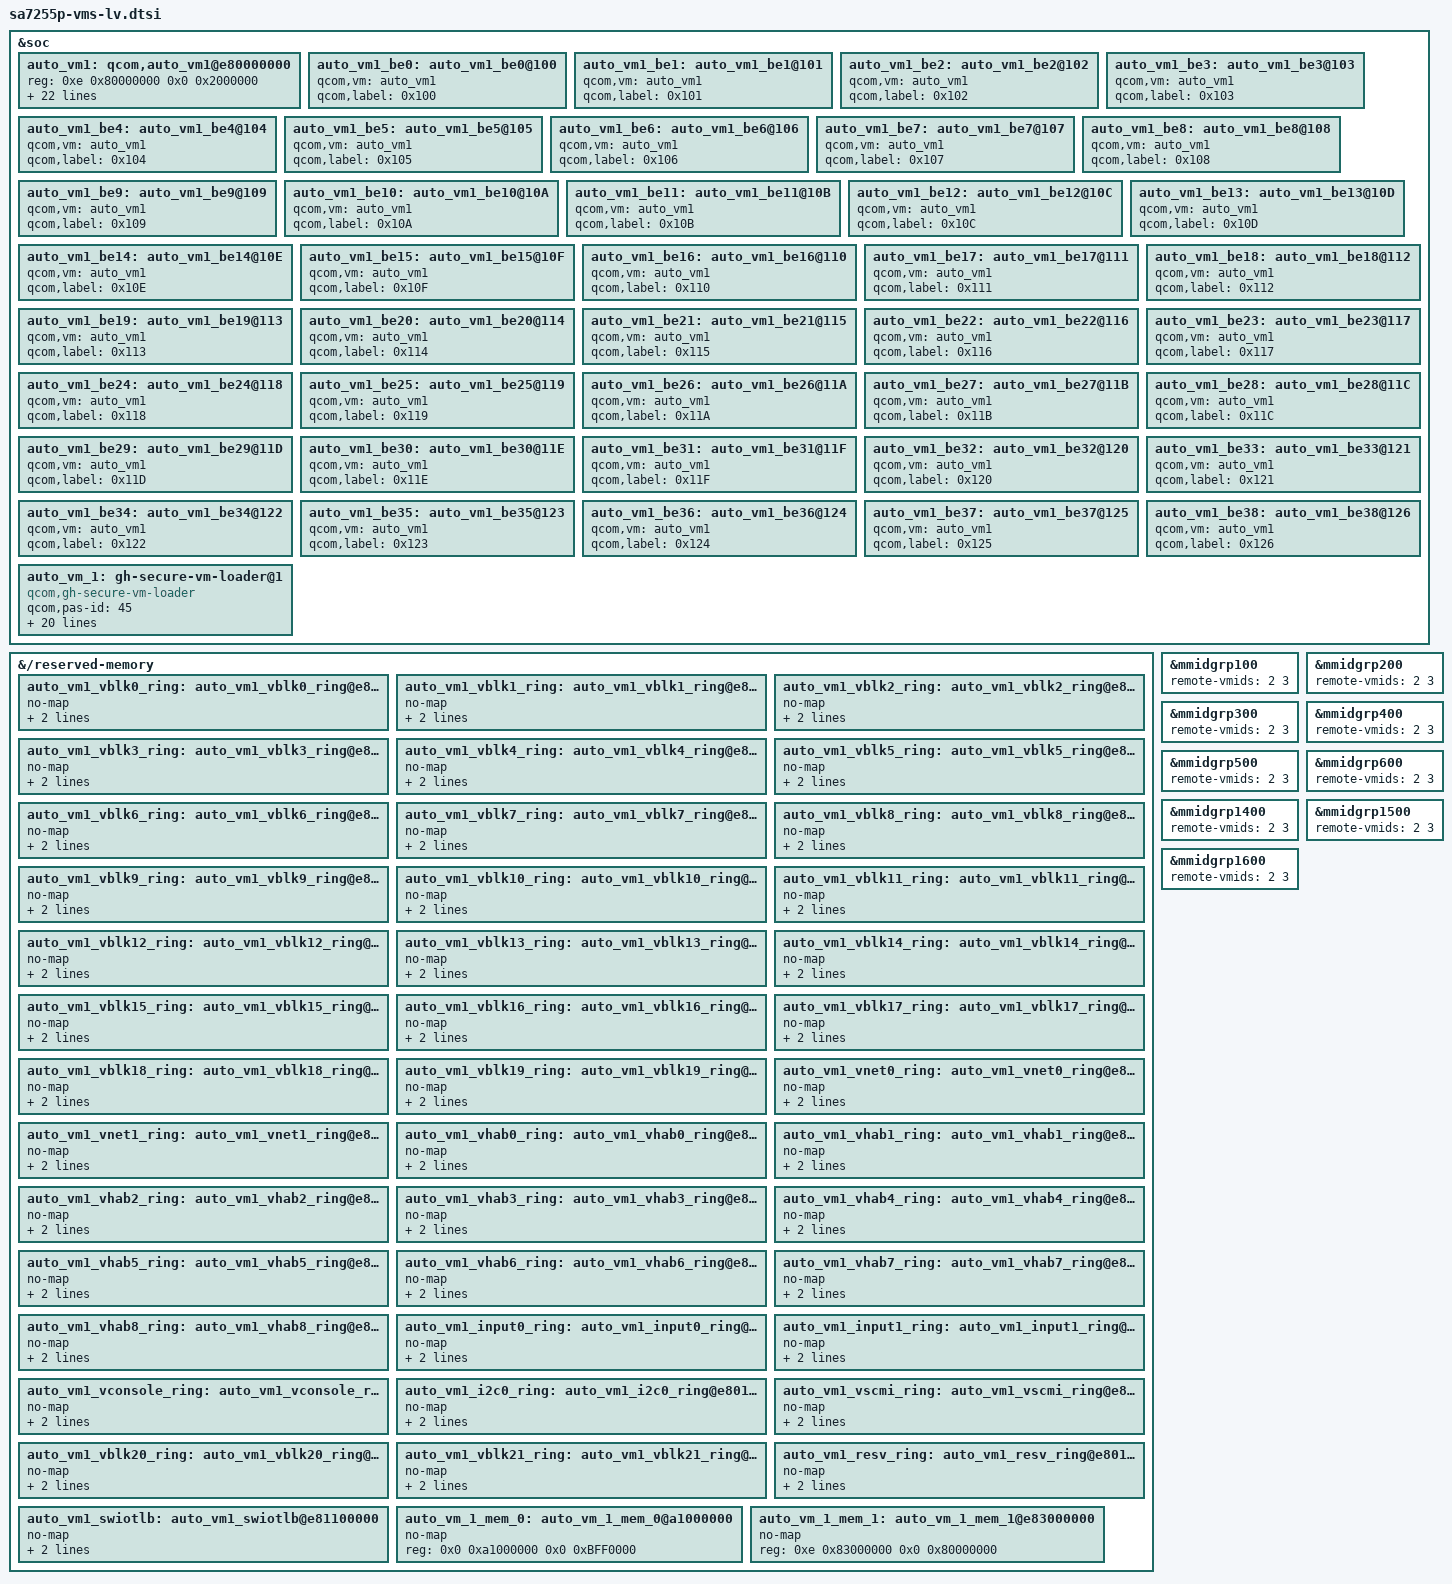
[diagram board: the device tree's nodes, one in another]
// SPDX-License-Identifier: BSD-3-Clause
/*
 * Copyright (c) Qualcomm Technologies, Inc. and/or its subsidiaries.
 */

&soc {
	auto_vm1: qcom,auto_vm1@e80000000 {
		reg = <0xe 0x80000000 0x0 0x2000000>; /*32MB*/
		vm_name = "autoghgvmlv";
		shared-buffers = <&auto_vm1_vblk0_ring
				&auto_vm1_vblk1_ring
				&auto_vm1_vblk2_ring
				&auto_vm1_vblk3_ring
				&auto_vm1_vblk4_ring
				&auto_vm1_vblk5_ring
				&auto_vm1_vblk6_ring
				&auto_vm1_vblk7_ring
				&auto_vm1_vblk8_ring
				&auto_vm1_vblk9_ring
				&auto_vm1_vblk10_ring
				&auto_vm1_vblk11_ring
				&auto_vm1_vblk12_ring
				&auto_vm1_vblk13_ring
				&auto_vm1_vblk14_ring
				&auto_vm1_vblk15_ring
				&auto_vm1_vblk16_ring
				&auto_vm1_vblk17_ring
				&auto_vm1_vblk18_ring
				&auto_vm1_vblk19_ring
				&auto_vm1_vblk20_ring
				&auto_vm1_vblk21_ring
				&auto_vm1_vnet0_ring
				&auto_vm1_vnet1_ring
				&auto_vm1_vhab0_ring
				&auto_vm1_vhab1_ring
				&auto_vm1_vhab2_ring
				&auto_vm1_vhab3_ring
				&auto_vm1_vhab4_ring
				&auto_vm1_vhab5_ring
				&auto_vm1_vhab6_ring
				&auto_vm1_vhab7_ring
				&auto_vm1_vhab8_ring
				&auto_vm1_input0_ring
				&auto_vm1_input1_ring
				&auto_vm1_vconsole_ring
				&auto_vm1_i2c0_ring
				&auto_vm1_vscmi_ring
				&auto_vm1_resv_ring
				&auto_vm1_swiotlb>;
	};

	auto_vm1_be0: auto_vm1_be0@100 {
		qcom,vm = <&auto_vm1>;
		qcom,label = <0x100>;
	};

	auto_vm1_be1: auto_vm1_be1@101 {
		qcom,vm = <&auto_vm1>;
		qcom,label = <0x101>;
	};

	auto_vm1_be2: auto_vm1_be2@102 {
		qcom,vm = <&auto_vm1>;
		qcom,label = <0x102>;
	};

	auto_vm1_be3: auto_vm1_be3@103 {
		qcom,vm = <&auto_vm1>;
		qcom,label = <0x103>;
	};

	auto_vm1_be4: auto_vm1_be4@104 {
		qcom,vm = <&auto_vm1>;
		qcom,label = <0x104>;
	};

	auto_vm1_be5: auto_vm1_be5@105 {
		qcom,vm = <&auto_vm1>;
		qcom,label = <0x105>;
	};

	auto_vm1_be6: auto_vm1_be6@106 {
		qcom,vm = <&auto_vm1>;
		qcom,label = <0x106>;
	};

	auto_vm1_be7: auto_vm1_be7@107 {
		qcom,vm = <&auto_vm1>;
		qcom,label = <0x107>;
	};

	auto_vm1_be8: auto_vm1_be8@108 {
		qcom,vm = <&auto_vm1>;
		qcom,label = <0x108>;
	};

	auto_vm1_be9: auto_vm1_be9@109 {
		qcom,vm = <&auto_vm1>;
		qcom,label = <0x109>;
	};

	auto_vm1_be10: auto_vm1_be10@10A {
		qcom,vm = <&auto_vm1>;
		qcom,label = <0x10A>;
	};

	auto_vm1_be11: auto_vm1_be11@10B {
		qcom,vm = <&auto_vm1>;
		qcom,label = <0x10B>;
	};

	auto_vm1_be12: auto_vm1_be12@10C {
		qcom,vm = <&auto_vm1>;
		qcom,label = <0x10C>;
	};

	auto_vm1_be13: auto_vm1_be13@10D {
		qcom,vm = <&auto_vm1>;
		qcom,label = <0x10D>;
	};

	auto_vm1_be14: auto_vm1_be14@10E {
		qcom,vm = <&auto_vm1>;
		qcom,label = <0x10E>;
	};

	auto_vm1_be15: auto_vm1_be15@10F {
		qcom,vm = <&auto_vm1>;
		qcom,label = <0x10F>;
	};

	auto_vm1_be16: auto_vm1_be16@110 {
		qcom,vm = <&auto_vm1>;
		qcom,label = <0x110>;
	};

	auto_vm1_be17: auto_vm1_be17@111 {
		qcom,vm = <&auto_vm1>;
		qcom,label = <0x111>;
	};

	auto_vm1_be18: auto_vm1_be18@112 {
		qcom,vm = <&auto_vm1>;
		qcom,label = <0x112>;
	};

	auto_vm1_be19: auto_vm1_be19@113 {
		qcom,vm = <&auto_vm1>;
		qcom,label = <0x113>;
	};

	auto_vm1_be20: auto_vm1_be20@114 {
		qcom,vm = <&auto_vm1>;
		qcom,label = <0x114>;
	};

	auto_vm1_be21: auto_vm1_be21@115 {
		qcom,vm = <&auto_vm1>;
		qcom,label = <0x115>;
	};

	auto_vm1_be22: auto_vm1_be22@116 {
		qcom,vm = <&auto_vm1>;
		qcom,label = <0x116>;
	};

	auto_vm1_be23: auto_vm1_be23@117 {
		qcom,vm = <&auto_vm1>;
		qcom,label = <0x117>;
	};

	auto_vm1_be24: auto_vm1_be24@118 {
		qcom,vm = <&auto_vm1>;
		qcom,label = <0x118>;
	};

	auto_vm1_be25: auto_vm1_be25@119 {
		qcom,vm = <&auto_vm1>;
		qcom,label = <0x119>;
	};

	auto_vm1_be26: auto_vm1_be26@11A {
		qcom,vm = <&auto_vm1>;
		qcom,label = <0x11A>;
	};

	auto_vm1_be27: auto_vm1_be27@11B {
		qcom,vm = <&auto_vm1>;
		qcom,label = <0x11B>;
	};

	auto_vm1_be28: auto_vm1_be28@11C {
		qcom,vm = <&auto_vm1>;
		qcom,label = <0x11C>;
	};

	auto_vm1_be29: auto_vm1_be29@11D {
		qcom,vm = <&auto_vm1>;
		qcom,label = <0x11D>;
	};

	auto_vm1_be30: auto_vm1_be30@11E {
		qcom,vm = <&auto_vm1>;
		qcom,label = <0x11E>;
	};

	auto_vm1_be31: auto_vm1_be31@11F {
		qcom,vm = <&auto_vm1>;
		qcom,label = <0x11F>;
	};

	auto_vm1_be32: auto_vm1_be32@120 {
		qcom,vm = <&auto_vm1>;
		qcom,label = <0x120>;
	};

	auto_vm1_be33: auto_vm1_be33@121 {
		qcom,vm = <&auto_vm1>;
		qcom,label = <0x121>;
	};

	auto_vm1_be34: auto_vm1_be34@122 {
		qcom,vm = <&auto_vm1>;
		qcom,label = <0x122>;
	};

	auto_vm1_be35: auto_vm1_be35@123 {
		qcom,vm = <&auto_vm1>;
		qcom,label = <0x123>;
	};

	auto_vm1_be36: auto_vm1_be36@124 {
		qcom,vm = <&auto_vm1>;
		qcom,label = <0x124>;
	};

        auto_vm1_be37: auto_vm1_be37@125 {
		qcom,vm = <&auto_vm1>;
		qcom,label = <0x125>;
	};

        auto_vm1_be38: auto_vm1_be38@126 {
		qcom,vm = <&auto_vm1>;
		qcom,label = <0x126>;
	};

	auto_vm_1: gh-secure-vm-loader@1 {
		compatible = "qcom,gh-secure-vm-loader";
		qcom,pas-id = <45>;
		qcom,vmid = <53>;
		qcom,firmware-name = "autoghgvmlv";
		qcom,firmware-index = <0>;
		memory-region = <&auto_vm_1_mem_0 &auto_vm_1_mem_1>;
		enable-gvm-dump;
		virtio-backends = <&auto_vm1_be0
				&auto_vm1_be1
				&auto_vm1_be2
				&auto_vm1_be3
				&auto_vm1_be4
				&auto_vm1_be5
				&auto_vm1_be6
				&auto_vm1_be7
				&auto_vm1_be8
				&auto_vm1_be9
				&auto_vm1_be10
				&auto_vm1_be11
				&auto_vm1_be12
				&auto_vm1_be13
				&auto_vm1_be14
				&auto_vm1_be15
				&auto_vm1_be16
				&auto_vm1_be17
				&auto_vm1_be18
				&auto_vm1_be19
				&auto_vm1_be20
				&auto_vm1_be21
				&auto_vm1_be22
				&auto_vm1_be23
				&auto_vm1_be24
				&auto_vm1_be25
				&auto_vm1_be26
				&auto_vm1_be27
				&auto_vm1_be28
				&auto_vm1_be29
				&auto_vm1_be30
				&auto_vm1_be31
				&auto_vm1_be32
				&auto_vm1_be33
				&auto_vm1_be34
				&auto_vm1_be35
				&auto_vm1_be36
                                &auto_vm1_be37
                                &auto_vm1_be38>;
	};
};

&{/reserved-memory} {
	#address-cells = <2>;
	#size-cells = <2>;
	ranges;

	auto_vm1_vblk0_ring: auto_vm1_vblk0_ring@e80000000 {
		no-map;
		reg = <0xe 0x80000000 0x0 0x4000>;
		gunyah-label = <0x100>;
	};

	auto_vm1_vblk1_ring: auto_vm1_vblk1_ring@e80004000 {
		no-map;
		reg = <0xe 0x80004000 0x0 0x4000>;
		gunyah-label = <0x101>;
	};

	auto_vm1_vblk2_ring: auto_vm1_vblk2_ring@e80008000 {
		no-map;
		reg = <0xe 0x80008000 0x0 0x4000>;
		gunyah-label = <0x102>;
	};

	auto_vm1_vblk3_ring: auto_vm1_vblk3_ring@e8000c000 {
		no-map;
		reg = <0xe 0x8000c000 0x0 0x4000>;
		gunyah-label = <0x103>;
	};

	auto_vm1_vblk4_ring: auto_vm1_vblk4_ring@e80010000 {
		no-map;
		reg = <0xe 0x80010000 0x0 0x4000>;
		gunyah-label = <0x104>;
	};

	auto_vm1_vblk5_ring: auto_vm1_vblk5_ring@e80014000 {
		no-map;
		reg = <0xe 0x80014000 0x0 0x4000>;
		gunyah-label = <0x105>;
	};

	auto_vm1_vblk6_ring: auto_vm1_vblk6_ring@e80018000 {
		no-map;
		reg = <0xe 0x80018000 0x0 0x4000>;
		gunyah-label = <0x106>;
	};

	auto_vm1_vblk7_ring: auto_vm1_vblk7_ring@e8001c000 {
		no-map;
		reg = <0xe 0x8001c000 0x0 0x4000>;
		gunyah-label = <0x107>;
	};

	auto_vm1_vblk8_ring: auto_vm1_vblk8_ring@e80020000 {
		no-map;
		reg = <0xe 0x80020000 0x0 0x4000>;
		gunyah-label = <0x108>;
	};

	auto_vm1_vblk9_ring: auto_vm1_vblk9_ring@e80024000 {
		no-map;
		reg = <0xe 0x80024000 0x0 0x4000>;
		gunyah-label = <0x109>;
	};

	auto_vm1_vblk10_ring: auto_vm1_vblk10_ring@e80028000 {
		no-map;
		reg = <0xe 0x80028000 0x0 0x4000>;
		gunyah-label = <0x10A>;
	};

	auto_vm1_vblk11_ring: auto_vm1_vblk11_ring@e8002c000 {
		no-map;
		reg = <0xe 0x8002C000 0x0 0x4000>;
		gunyah-label = <0x10B>;
	};

	auto_vm1_vblk12_ring: auto_vm1_vblk12_ring@e80030000 {
		no-map;
		reg = <0xe 0x80030000 0x0 0x4000>;
		gunyah-label = <0x10C>;
	};

	auto_vm1_vblk13_ring: auto_vm1_vblk13_ring@e80034000 {
		no-map;
		reg = <0xe 0x80034000 0x0 0x4000>;
		gunyah-label = <0x10D>;
	};

	auto_vm1_vblk14_ring: auto_vm1_vblk14_ring@e80038000 {
		no-map;
		reg = <0xe 0x80038000 0x0 0x4000>;
		gunyah-label = <0x10E>;
	};

	auto_vm1_vblk15_ring: auto_vm1_vblk15_ring@e8003c000 {
		no-map;
		reg = <0xe 0x8003C000 0x0 0x4000>;
		gunyah-label = <0x10F>;
	};

	auto_vm1_vblk16_ring: auto_vm1_vblk16_ring@e80040000 {
		no-map;
		reg = <0xe 0x80040000 0x0 0x4000>;
		gunyah-label = <0x110>;
	};

	auto_vm1_vblk17_ring: auto_vm1_vblk17_ring@e80044000 {
		no-map;
		reg = <0xe 0x80044000 0x0 0x4000>;
		gunyah-label = <0x111>;
	};

	auto_vm1_vblk18_ring: auto_vm1_vblk18_ring@e80048000 {
		no-map;
		reg = <0xe 0x80048000 0x0 0x4000>;
		gunyah-label = <0x112>;
	};

	auto_vm1_vblk19_ring: auto_vm1_vblk19_ring@e8004c000 {
		no-map;
		reg = <0xe 0x8004C000 0x0 0x4000>;
		gunyah-label = <0x113>;
	};

	auto_vm1_vnet0_ring: auto_vm1_vnet0_ring@e80050000 {
		no-map;
		reg = <0xe 0x80050000 0x0 0x8000>;
		gunyah-label = <0x114>;
	};

	auto_vm1_vnet1_ring: auto_vm1_vnet1_ring@e80058000 {
		no-map;
		reg = <0xe 0x80058000 0x0 0x8000>;
		gunyah-label = <0x115>;
	};

	auto_vm1_vhab0_ring: auto_vm1_vhab0_ring@e80060000 {
		no-map;
		reg = <0xe 0x80060000 0x0 0x10000>;
		gunyah-label = <0x116>;
	};

	auto_vm1_vhab1_ring: auto_vm1_vhab1_ring@e80070000 {
		no-map;
		reg = <0xe 0x80070000 0x0 0x10000>;
		gunyah-label = <0x117>;
	};

	auto_vm1_vhab2_ring: auto_vm1_vhab2_ring@e80080000 {
		no-map;
		reg = <0xe 0x80080000 0x0 0x40000>;
		gunyah-label = <0x118>;
	};

	auto_vm1_vhab3_ring: auto_vm1_vhab3_ring@e800c0000 {
		no-map;
		reg = <0xe 0x800C0000 0x0 0x50000>;
		gunyah-label = <0x119>;
	};

	auto_vm1_vhab4_ring: auto_vm1_vhab4_ring@e80110000 {
		no-map;
		reg = <0xe 0x80110000 0x0 0x30000>;
		gunyah-label = <0x11A>;
	};

	auto_vm1_vhab5_ring: auto_vm1_vhab5_ring@e80140000 {
		no-map;
		reg = <0xe 0x80140000 0x0 0x30000>;
		gunyah-label = <0x11B>;
	};

	auto_vm1_vhab6_ring: auto_vm1_vhab6_ring@e80170000 {
		no-map;
		reg = <0xe 0x80170000 0x0 0x10000>;
		gunyah-label = <0x11C>;
	};

	auto_vm1_vhab7_ring: auto_vm1_vhab7_ring@e80180000 {
		no-map;
		reg = <0xe 0x80180000 0x0 0x10000>;
		gunyah-label = <0x11D>;
	};

	auto_vm1_vhab8_ring: auto_vm1_vhab8_ring@e80190000 {
		no-map;
		reg = <0xe 0x80190000 0x0 0x30000>;
		gunyah-label = <0x11E>;
	};

	auto_vm1_input0_ring: auto_vm1_input0_ring@e801c0000 {
		no-map;
		reg = <0xe 0x801C0000 0x0 0x4000>;
		gunyah-label = <0x11F>;
	};

	auto_vm1_input1_ring: auto_vm1_input1_ring@e801c4000 {
		no-map;
		reg = <0xe 0x801C4000 0x0 0x4000>;
		gunyah-label = <0x120>;
	};

	auto_vm1_vconsole_ring: auto_vm1_vconsole_ring@e801c8000 {
		no-map;
		reg = <0xe 0x801C8000 0x0 0x4000>;
		gunyah-label = <0x121>;
	};

	auto_vm1_i2c0_ring: auto_vm1_i2c0_ring@e801cc000 {
		no-map;
		reg = <0xe 0x801CC000 0x0 0x2000>;
		gunyah-label = <0x122>;
	};

	auto_vm1_vscmi_ring: auto_vm1_vscmi_ring@e801ce000 {
		no-map;
		reg = <0xe 0x801CE000 0x0 0x8000>;
		gunyah-label = <0x123>;
	};

	auto_vm1_vblk20_ring: auto_vm1_vblk20_ring@e801d6000 {
		no-map;
		reg = <0xe 0x801D6000 0x0 0x4000>;
		gunyah-label = <0x124>;
	};

	auto_vm1_vblk21_ring: auto_vm1_vblk21_ring@e801da000 {
		no-map;
		reg = <0xe 0x801DA000 0x0 0x4000>;
		gunyah-label = <0x125>;
	};

	auto_vm1_resv_ring: auto_vm1_resv_ring@e801de000 {
		no-map;
		reg = <0xe 0x801DE000 0x0 0xF22000>;
		gunyah-label = <0x126>;
	};

	auto_vm1_swiotlb: auto_vm1_swiotlb@e81100000 {
		no-map;
		reg = <0xe 0x81100000 0x0 0xF00000>;
		gunyah-label = <0x140>;
	};

	auto_vm_1_mem_0: auto_vm_1_mem_0@a1000000 {
		no-map;
		reg = <0x0 0xa1000000 0x0 0xBFF0000>; /*191MB*/
	};

	auto_vm_1_mem_1: auto_vm_1_mem_1@e83000000 {
		no-map;
		reg = <0xe 0x83000000 0x0 0x80000000>; /*2GB*/
	};
};

&mmidgrp100 {
	remote-vmids = <2 3>;
};

&mmidgrp200 {
	remote-vmids = <2 3>;
};

&mmidgrp300 {
	remote-vmids = <2 3>;
};

&mmidgrp400 {
	remote-vmids = <2 3>;
};

&mmidgrp500 {
	remote-vmids = <2 3>;
};

&mmidgrp600 {
	remote-vmids = <2 3>;
};

&mmidgrp1400 {
	remote-vmids = <2 3>;
};

&mmidgrp1500 {
	remote-vmids = <2 3>;
};

&mmidgrp1600 {
	remote-vmids = <2 3>;
};
